# STM32H7RSxx register map
File version: 0.2
CPU: CM7 r0p1, little endian, MPU, FPU, 4 interrupt priority bits
Registers are 32-bit, read-write, reset 0x0 unless marked. A register's access mark holds for its fields unless they carry their own. Offsets are from the block's base; [hi:lo] are bit positions; {n}, {i} and the like mark numbered series; 'fields as' and 'values as' point back to an identical list; <NAME> marks a mode.

## SBS — System configuration, boot and security
Base 0x58000400
0x00 SBS_BOOTSR ro — SBS boot status register
  [31:0] INITVTOR — initial vector for Cortex-M7 This register includes the physical boot address used by the Cortex-M7 after reset
0x10 SBS_HDPLCR reset 0xB4 — SBS hide protection control register
  [7:0] INCR_HDPL — increment HDPL Write 0x6A to increment device HDPL by one. After a write, the register value reverts to its default value (0xB4).
0x14 SBS_HDPLSR ro (reset mask 0xFFFFFF00) — SBS hide protection status register
  [7:0] HDPL — hide protection level This bitfield returns the current HDPL of the device. 0x6F and other codes: HDPL3, corresponding to non-boot application. Note: The device state (open/close) is defined in FLASH_NVSTATER register of the embedded Flash memory.
    180=HDPL0, corresponding to ST-RSS (default when device is close); 81=HDPL1; 138=HDPL2
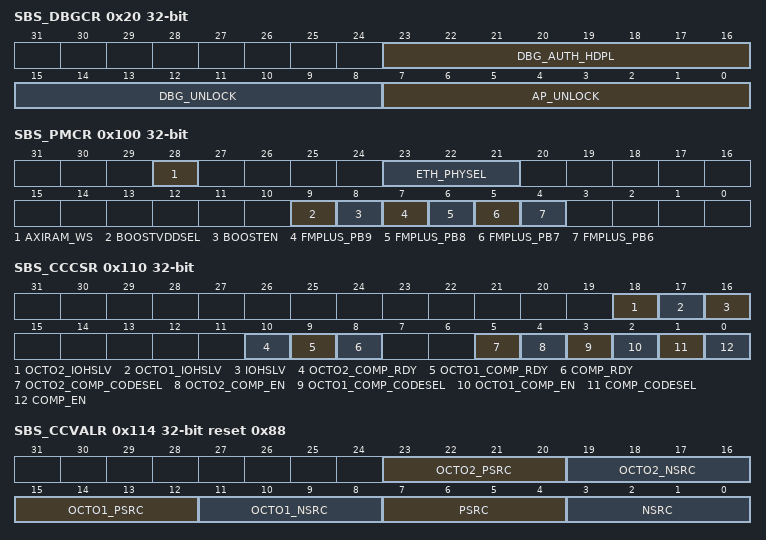
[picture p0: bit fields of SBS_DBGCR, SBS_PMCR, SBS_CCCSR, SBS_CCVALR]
0x20 SBS_DBGCR — SBS debug control register
  [23:16] DBG_AUTH_HDPL — authenticated debug hide protection level Writing to this bitfield defines at which HDPL the authenticated debug opens. Note: Writing any other values is ignored. Reading any other value means the authenticated debug always fails.
    81=HDPL1; 138=HDPL2; 111=HDPL3
  [15:8] DBG_UNLOCK — debug unlock Write 0xB4 to this bitfield to open the debug when HDPL in SBS_HDPLSR equals to DBG_AUTH_HDPL in this register.
  [7:0] AP_UNLOCK — access port unlock Write 0xB4 to this bitfield to open the device access port.
0x24 SBS_DBGLOCKR reset 0xB4 — SBS debug lock register
  [7:0] DBGCFG_LOCK — debug configuration lock Reading this bitfield returns 0x6A if the bitfield value is different from 0xB4. Other: Writes to SBS_DBGCR ignored Note: 0xC3 is the recommended value to lock the debug configuration using this bitfield.
    180=Writes to SBS_DBGCR allowed (default)
0x34 SBS_RSSCMDR — SBS RSS command register
  [15:0] RSSCMD — RSS command The application can use this bitfield to pass on a command to the RSS, executed at the next reset.
0x100 SBS_PMCR — SBS product mode and configuration register
  [28] AXIRAM_WS — AXIRAM wait state Set this bit to add one wait state to all AXIRAMs when ECC = 0. When ECC = 1 there is one wait state by default.
    0=No wait state added when accessing any AXIRAM with ECC = 0; 1=One wait state added when accessing any AXIRAM with ECC = 0. In this case, Fmax = 500 MHz is not guaranteed. (TBC)
  [23:21] ETH_PHYSEL — Ethernet PHY interface selection Other: reserved
    0=GMII or MII; 4=RMII
  [9] BOOSTVDDSEL — booster V<sub>DD</sub> selection This bit selects the analog switch supply voltage, between V<sub>DD</sub>, V<sub>DDA</sub> and booster. To avoid current consumption due to booster activation when V<sub>DDA</sub> < 2.7 V and V<sub>DD</sub> > 2.7 V, V<sub>DD</sub> can be selected as supply voltage for analog switches. In this case, the BOOSTEN bit must be cleared to avoid unwanted power consumption. When both V<sub>DD and </sub>V<sub>DDA</sub> are below 2.7 V, the booster is still needed to obtain full AC performances from the I/O analog switches.
    0=V<sub>DDA</sub> selected as analog switch booster voltage supply (when BOOSTEN bit is cleared); 1=V<sub>DD</sub> selected as analog switch booster voltage supply
  [8] BOOSTEN — booster enable Set this bit to reduce the THD of the analog switches when the supply voltage is below 2.7 V. guaranteeing the same performance as with the full voltage range. To avoid current consumption due to booster activation when V<sub>DDA</sub> < 2.7 V and V<sub>DD</sub> > 2.7 V, V<sub>DD</sub> can be selected as supply voltage for analog switches by setting BOOSTVDDSEL bit in SBS_PMCR. In this case, the BOOSTEN bit must be cleared to avoid unwanted power consumption.
    0=Booster disabled; 1=Booster enabled
  [7] FMPLUS_PB9 — Fast-mode Plus on PB(9)
    0=I2C Fast-mode Plus mode disabled on PB(9); 1=Fast-mode Plus mode enabled on PB(9)
  [6] FMPLUS_PB8 — Fast-mode Plus on PB(8)
    0=Fast-mode Plus mode disabled on PB(8); 1=Fast-mode Plus mode enabled on PB(8)
  [5] FMPLUS_PB7 — Fast-mode Plus on PB(7)
    0=Fast-mode Plus mode disabled on PB(7); 1=Fast mode plus mode enabled on PB(7)
  [4] FMPLUS_PB6 — Fast-mode Plus on PB(6)
    0=Fast-mode Plus mode disabled on PB(6); 1=Fast-mode Plus mode enabled on PB(6)
0x104 SBS_FPUIMR reset 0x1F — SBS FPU interrupt mask register
  [5:0] FPU_IE — FPU interrupt enable Set and cleared by software to enable the Cortex-M7 FPU interrupts xxxxx1: Invalid operation interrupt enabled (xxxxx0 to disable) xxxx1x: Divide-by-zero interrupt enabled (xxxx0x to disable) xxx1xx: Underflow interrupt enabled (xxx0xx to disable) xx1xxx: Overflow interrupt enabled (xx0xxx to disable) x1xxxx: Input denormal interrupt enabled (x0xxxx to disable) 1xxxxx: Inexact interrupt enabled (0xxxxx to disable), disabled by default
0x108 SBS_MESR ro — SBS memory erase status register
  [0] MEF — memory erase flag This bit is set by hardware when BKPRAM and PKA SRAM erase is ongoing after a power‑on reset or one tamper event (see Section 50: Tamper and backup registers (TAMP) for details). This bit is cleared when the erase is done.
    0=Automatic erase of BKPRAM and PKA RAM memories ongoing; 1=Automatic erase of BKPRAM and PKA RAM memories done
0x110 SBS_CCCSR access per field — SBS I/O compensation cell control and status register
  [18] OCTO2_IOHSLV rw — XSPIM_P2 I/O high speed at low voltage When this bit is set, the speed of the XSPIM_P2 I/Os is optimized when the device voltage is low. This bit is active only if OCTO2_HSLV user option bit is set in FLASH. This bit must be used only if the device supply voltage is below 2.7 V. Setting this bit when V<sub>DD</sub> is higher than 2.7 V may be destructive.
    0=No XSPIM_P2 I/O speed optimization when device voltage is low; 1=XSPIM_P2 I/O speed optimized when device voltage is low, if OCTO2_HSLV user option is set (no effect otherwise)
  [17] OCTO1_IOHSLV rw — XSPIM_P1 I/O high speed at low voltage When this bit is set, the speed of the XSPIM_P1 I/Os is optimized when the device voltage is low. This bit is active only if OCTO1_HSLV user option bit is set in FLASH. This bit must be used only if the device supply voltage is below 2.7 V. Setting this bit when V<sub>DD</sub> is higher than 2.7 V may be destructive.
    0=No XSPIM_P1 I/O speed optimization when device voltage is low; 1=XSPIM_P1 I/O speed optimized when device voltage is low, if OCTO1_HSLV user option is set (no effect otherwise)
  [16] IOHSLV rw — I/O high speed at low voltage When this bit is set, the speed of the I/Os is optimized when the device voltage is low. This bit is active only if VDDIO_HSLV user option bit is set in FLASH. It must be used only if the device supply voltage is below 2.7 V. Setting this bit when V<sub>DD</sub> is higher than 2.7 V may be destructive.
    0=No I/O speed optimization when device voltage is low; 1=I/O speed optimized when device voltage is low, if VDDIO_HSLV user option is set (no effect otherwise)
  [10] OCTO2_COMP_RDY ro — XSPIM_P2 compensation cell ready This bit provides the status of the XSPIM_P2 compensation cell.
    0=XSPIM_P2 I/O compensation cell not ready; 1=XSPIM_P2 I/O compensation cell ready. The code value provided by the cell can be used.
  [9] OCTO1_COMP_RDY ro — XSPIM_P1 compensation cell ready This bit provides the status of the XSPIM_P1 compensation cell.
    0=XSPIM_P1 I/O compensation cell not ready; 1=XSPIM_P1 I/O compensation cell ready. The code value provided by the cell can be used.
  [8] COMP_RDY ro — Compensation cell ready This bit provides the status of the compensation cell.
    0=I/O compensation cell not ready; 1=I/O compensation cell ready. The code value provided by the cell can be used.
  [5] OCTO2_COMP_CODESEL ro — XSPIM_P2 compensation cell code selection This bit selects the code to be applied for the XSPIM_P2 I/O compensation cell.
    0=Code from the cell (available in the SBS_CCVALR); 1=Code from the SBS software value register (SBS_CCSWVALR)
  [4] OCTO2_COMP_EN ro — XSPIM_P2 compensation cell enable Set this bit to enable the XSPIM_P2 compensation cell.
    0=XSPIM_P2 compensation cell disabled; 1=XSPIM_P2 compensation cell enabled
  [3] OCTO1_COMP_CODESEL rw — XSPIM_P1 compensation cell code selection This bit selects the code to be applied for the XSPIM_P1 I/O compensation cell.
    values as OCTO2_COMP_CODESEL
  [2] OCTO1_COMP_EN rw — XSPIM_P1 compensation cell enable Set this bit to enable the XSPIM_P1 compensation cell.
    0=XSPIM_P1 compensation cell disabled; 1=XSPIM_P1 compensation cell enabled
  [1] COMP_CODESEL rw — Compensation cell code selection This bit selects the code to be applied for the I/O compensation cell.
    values as OCTO2_COMP_CODESEL
  [0] COMP_EN rw — Compensation cell enable Set this bit to enable the compensation cell.
    0=Compensation cell disabled; 1=Compensation cell enabled
0x114 SBS_CCVALR ro reset 0x88 — SBS compensation cell for I/Os value register
  [23:20] OCTO2_PSRC — XSPIM_P2 PMOS transistors slew-rate compensation This bitfield returns the PMOS transistors slew-rate compensation value computed by the cell. It is interpreted by XSPIM_P2 to compensate the PMOS transistors slew rate in the functional range if OCTO2_COMP_CODESEL = 0 in SBS_CCCSR register.
  [19:16] OCTO2_NSRC — XSPIM_P2 NMOS transistors slew-rate compensation This bitfield returns the NMOS transistors slew-rate compensation value computed by the cell. It is interpreted by XSPIM_P2 to compensate the NMOS transistors slew rate in the functional range if OCTO2_COMP_CODESEL = 0 in SBS_CCCSR register.
  [15:12] OCTO1_PSRC — XSPIM_P1 PMOS transistors slew-rate compensation This bitfield returns the PMOS transistors slew-rate compensation value computed by the cell. It is interpreted by XSPIM_P1 to compensate the PMOS transistors slew rate in the functional range if OCTO1_COMP_CODESEL = 0 in SBS_CCCSR register.
  [11:8] OCTO1_NSRC — XSPIM_P1 NMOS transistors slew-rate compensation This bitfield returns the NMOS transistors slew-rate compensation value computed by the cell. It is interpreted by XSPIM_P1 to compensate the NMOS transistors slew rate in the functional range if OCTO1_COMP_CODESEL = 0 in SBS_CCCSR register.
  [7:4] PSRC — PMOS transistors slew-rate compensation This bitfield returns the PMOS transistors slew-rate compensation value computed by the cell. It is interpreted to compensate the PMOS transistors slew rate in the functional range if COMP_CODESEL = 0 in SBS_CCCSR register.
  [3:0] NSRC — NMOS transistors slew-rate compensation This bitfield returns the NMOS transistors slew-rate compensation value computed by the cell. It is interpreted to compensate the NMOS transistors slew rate in the functional range if COMP_CODESEL = 0 in SBS_CCCSR register.
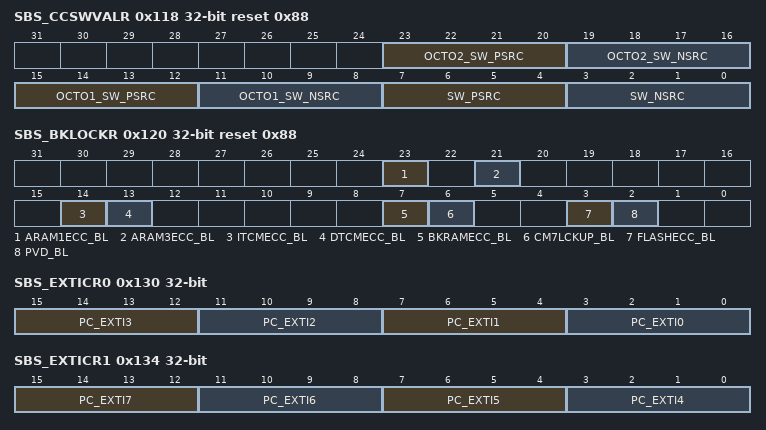
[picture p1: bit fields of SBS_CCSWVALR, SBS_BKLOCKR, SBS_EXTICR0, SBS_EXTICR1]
0x118 SBS_CCSWVALR reset 0x88 — SBS compensation cell for I/Os software value register
  [23:20] OCTO2_SW_PSRC — XSPIM_P2 software PMOS transistors slew-rate compensation This bitfield returns the PMOS transistors slew-rate compensation value computed by the cell. It is interpreted by XSPIM_P2 to compensate the PMOS transistors slew rate in the functional range if OCTO2_COMP_CODESEL = 1 in SBS_CCCSR register.
  [19:16] OCTO2_SW_NSRC — XSPIM_P2 software NMOS transistors slew-rate compensation This bitfield returns the NMOS transistors slew-rate compensation value computed by the cell. It is interpreted by XSPIM_P2 to compensate the NMOS transistors slew rate in the functional range if OCTO2_COMP_CODESEL = 1 in SBS_CCCSR register.
  [15:12] OCTO1_SW_PSRC — XSPIM_P1 software PMOS transistors slew-rate compensation This bitfield returns the PMOS transistors slew-rate compensation value computed by the cell. It is interpreted by XSPIM_P1 to compensate the PMOS transistors slew rate in the functional range if OCTO1_COMP_CODESEL = 1 in SBS_CCCSR register.
  [11:8] OCTO1_SW_NSRC — XSPIM_P1 software NMOS transistors slew-rate compensation This bitfield returns the NMOS transistors slew -ate compensation value computed by the cell. It is interpreted by XSPIM_P1 to compensate the NMOS transistors slew rate in the functional range if OCTO1_COMP_CODESEL = 1 in SBS_CCCSR register.
  [7:4] SW_PSRC — Software PMOS transistors slew-rate compensation This bitfield returns the PMOS transistors slew-rate compensation value computed by the cell. It is interpreted to compensate the PMOS transistors slew rate in the functional range if COMP_CODESEL = 1 in SBS_CCCSR register.
  [3:0] SW_NSRC — Software NMOS transistors slew-rate compensation This bitfield returns the NMOS transistors slew-rate compensation value computed by the cell. It is interpreted to compensate the NMOS transistors slew rate in the functional range if COMP_CODESEL = 1 in SBS_CCCSR register.
0x120 SBS_BKLOCKR reset 0x88 — SBS break lockup register
  [23] ARAM1ECC_BL — AXIRAM1 ECC error break lock Set this bit to enable and lock the connection between AXIRAM1 ECC double error detection flag and break inputs of TIM1/15/16/17 peripherals. Once set, this bit is cleared only by a system reset.
    0=AXIRAM1 ECC double error detection flag disconnected from TIM1/5/16/17 break inputs; 1=AXIRAM1 ECC double error detection flag connected to TIM1/15/16/17 break inputs
  [21] ARAM3ECC_BL — AXIRAM3 ECC error break lock Set this bit to enable and lock the connection between AXIRAM3 ECC double error detection flag and break inputs of TIM1/15/16/17 peripherals. Once set this bit is cleared only by a system reset.
    0=AXIRAM3 ECC double error detection flag disconnected from TIM1/15/16/17 break inputs; 1=AXIRAM3 ECC double error detection flag connected to TIM1/15/16/17 break inputs
  [14] ITCMECC_BL — ITCM ECC error break lock Set this bit to enable and lock the connection between ITCM ECC double error detection flag and break inputs of TIM1/15/16/17 peripherals. Once set, this bit is cleared only by a system reset.
    0=ITCM ECC double error detection flag disconnected from TIM1/15/16/17 break inputs; 1=ITCM ECC double error detection flag connected to TIM1/15/16/17 break inputs
  [13] DTCMECC_BL — DTCM ECC error break lock Set this bit to enable and lock the connection between DTCM ECC double error detection flag and break inputs of TIM1/15/16/17 peripherals. Once set, this bit is cleared only by a system reset. Note: The DTCM0 and DTCM1 are Or’ed to give DTCMECC
    0=DTCM ECC double error detection flag disconnected from TIM1/15/16/17 break inputs; 1=DTCM ECC double error detection flag connected to TIM1/15/16/17 break inputs
  [7] BKRAMECC_BL — Backup RAM ECC error break lock Set this bit to enable and lock the connection between backup RAM ECC double error detection flag and break inputs of TIM1/15/16/17 peripherals. Once set, this bit is cleared only by a system reset.
    0=Backup RAM ECC double error detection flag disconnected from TIM1/15/16/17 break inputs; 1=Backup RAM ECC double error detection flag connected to TIM1/15/16/17 break inputs
  [6] CM7LCKUP_BL — Cortex-M7 lockup break lock Set this bit to enable and lock the connection between the Cortex-M7 lockup (HardFault) output and break inputs of TIM1/15/16/17 peripherals. Once set, this bit is cleared only by a system reset.
    0=Cortex-M7 lockup output disconnected from TIM1/15/16/17 break inputs; 1=Cortex-M7 lockup output connected to TIM1/15/16/17 break inputs
  [3] FLASHECC_BL — Flash ECC error break lock Set this bit to enable and lock the connection between embedded flash memory ECC double error detection flag and break inputs of TIM1/15/16/17 peripherals. Once set, this bit is cleared only by a system reset.
    0=FLASH ECC double error detection flag disconnected from TIM1/15/16/17 break inputs; 1=FLASH ECC double error detection flag connected to TIM1/15/16/17 break inputs
  [2] PVD_BL — PVD break lock This bit is set by SW and cleared only by a system reset. it can be used to enable and lock the connection to TIM1/8/15/16/17Break input as well as the PVDE and PLS[2:0] bitfields in the PWR_CR1 register. Once set, this bit is cleared only by a system reset.
    0=PVD interrupt disconnected from TIM1/8/15/16/17 break inputs. PVDE and PLS[2:0] bitfields can be programmed by the application.; 1=PVD output connected to TIM1/8/15/16/17 break input. PVDE and PLS[2:0] bits are read only.
0x130 SBS_EXTICR0 ro — SBS external interrupt configuration register 0
  [all] fields
    0=PA[x*4+i] pin; 1=PB[x*4+i] pin; 2=PC[x*4+i] pin; 3=PD[x*4+i] pin; 4=PE[x*4+i] pin; 5=PF[x*4+i] pin; 6=PG[x*4+i] pin; 7=PH[x*4+i] pin; 8=PM[x*4+i] pin; 9=PN[x*4+i] pin; 16=PO[x*4+i] pin; 17=PP[x*4+i] pin
  [15:12] PC_EXTI3 — Port configuration EXTI {0 * 4 + i} This bitfield selects the source input to the EXTI input {0 * 4 + i} used for external interrupt/ event detection. Others: reserved
  [11:8] PC_EXTI2 — Port configuration EXTI {0 * 4 + i} This bitfield selects the source input to the EXTI input {0 * 4 + i} used for external interrupt/ event detection. Others: reserved
  [7:4] PC_EXTI1 — Port configuration EXTI {0 * 4 + i} This bitfield selects the source input to the EXTI input {0 * 4 + i} used for external interrupt/ event detection. Others: reserved
  [3:0] PC_EXTI0 — Port configuration EXTI {0 * 4 + i} This bitfield selects the source input to the EXTI input {0 * 4 + i} used for external interrupt/ event detection. Others: reserved
0x134 SBS_EXTICR1 ro — SBS external interrupt configuration register 1
  [all] fields
    values as the fields of SBS_EXTICR0
  [15:12] PC_EXTI7 — Port configuration EXTI {1 * 4 + i} This bitfield selects the source input to the EXTI input {1 * 4 + i} used for external interrupt/ event detection. Others: reserved
  [11:8] PC_EXTI6 — Port configuration EXTI {1 * 4 + i} This bitfield selects the source input to the EXTI input {1 * 4 + i} used for external interrupt/ event detection. Others: reserved
  [7:4] PC_EXTI5 — Port configuration EXTI {1 * 4 + i} This bitfield selects the source input to the EXTI input {1 * 4 + i} used for external interrupt/ event detection. Others: reserved
  [3:0] PC_EXTI4 — Port configuration EXTI {1 * 4 + i} This bitfield selects the source input to the EXTI input {1 * 4 + i} used for external interrupt/ event detection. Others: reserved
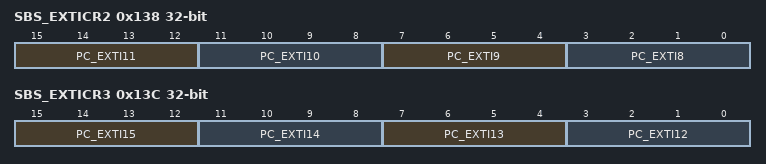
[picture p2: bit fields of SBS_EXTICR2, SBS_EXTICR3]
0x138 SBS_EXTICR2 ro — SBS external interrupt configuration register 2
  [all] fields
    values as the fields of SBS_EXTICR0
  [15:12] PC_EXTI11 — Port configuration EXTI {2 * 4 + i} This bitfield selects the source input to the EXTI input {2 * 4 + i} used for external interrupt/ event detection. Others: reserved
  [11:8] PC_EXTI10 — Port configuration EXTI {2 * 4 + i} This bitfield selects the source input to the EXTI input {2 * 4 + i} used for external interrupt/ event detection. Others: reserved
  [7:4] PC_EXTI9 — Port configuration EXTI {2 * 4 + i} This bitfield selects the source input to the EXTI input {2 * 4 + i} used for external interrupt/ event detection. Others: reserved
  [3:0] PC_EXTI8 — Port configuration EXTI {2 * 4 + i} This bitfield selects the source input to the EXTI input {2 * 4 + i} used for external interrupt/ event detection. Others: reserved
0x13C SBS_EXTICR3 ro — SBS external interrupt configuration register 3
  [all] fields
    values as the fields of SBS_EXTICR0
  [15:12] PC_EXTI15 — Port configuration EXTI {3 * 4 + i} This bitfield selects the source input to the EXTI input {3 * 4 + i} used for external interrupt/ event detection. Others: reserved
  [11:8] PC_EXTI14 — Port configuration EXTI {3 * 4 + i} This bitfield selects the source input to the EXTI input {3 * 4 + i} used for external interrupt/ event detection. Others: reserved
  [7:4] PC_EXTI13 — Port configuration EXTI {3 * 4 + i} This bitfield selects the source input to the EXTI input {3 * 4 + i} used for external interrupt/ event detection. Others: reserved
  [3:0] PC_EXTI12 — Port configuration EXTI {3 * 4 + i} This bitfield selects the source input to the EXTI input {3 * 4 + i} used for external interrupt/ event detection. Others: reserved
